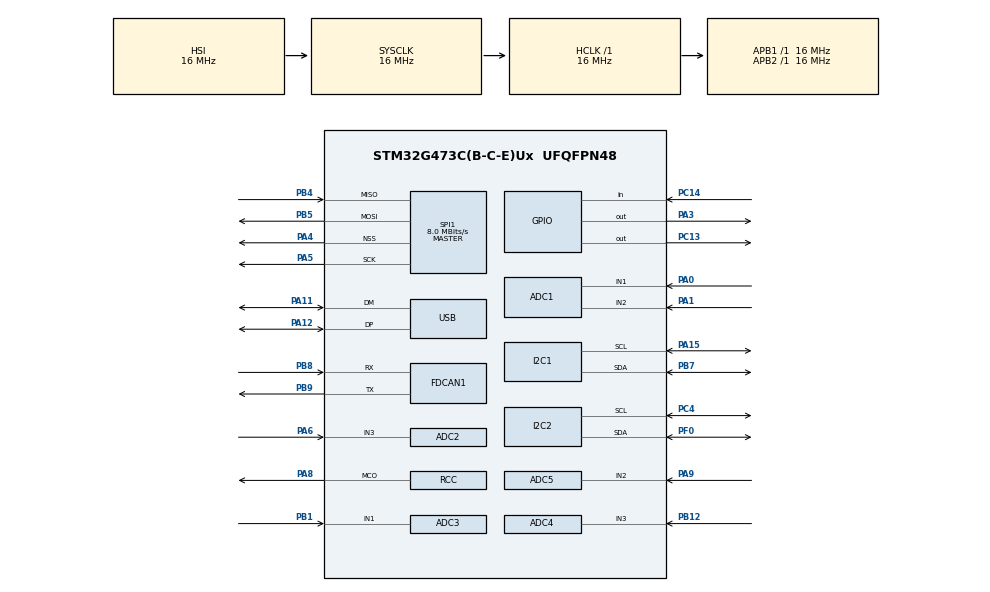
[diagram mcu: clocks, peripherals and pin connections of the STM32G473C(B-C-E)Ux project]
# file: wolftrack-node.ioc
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ADC1.Channel-0\#ChannelRegularConversion=ADC_CHANNEL_1
ADC1.NbrOfConversionFlag=1
ADC1.OffsetNumber-0\#ChannelRegularConversion=ADC_OFFSET_NONE
ADC1.Rank-0\#ChannelRegularConversion=1
ADC1.SamplingTime-0\#ChannelRegularConversion=ADC_SAMPLETIME_2CYCLES_5
ADC1.master=1
ADC2.Channel-3\#ChannelRegularConversion=ADC_CHANNEL_3
ADC2.NbrOfConversionFlag=1
ADC2.OffsetNumber-3\#ChannelRegularConversion=ADC_OFFSET_NONE
ADC2.Rank-3\#ChannelRegularConversion=1
ADC2.SamplingTime-3\#ChannelRegularConversion=ADC_SAMPLETIME_2CYCLES_5
ADC3.Channel-2\#ChannelRegularConversion=ADC_CHANNEL_1
ADC3.NbrOfConversionFlag=1
ADC3.OffsetNumber-2\#ChannelRegularConversion=ADC_OFFSET_NONE
ADC3.Rank-2\#ChannelRegularConversion=1
ADC3.SamplingTime-2\#ChannelRegularConversion=ADC_SAMPLETIME_2CYCLES_5
ADC3.master=1
ADC4.Channel-1\#ChannelRegularConversion=ADC_CHANNEL_3
ADC4.NbrOfConversionFlag=1
ADC4.OffsetNumber-1\#ChannelRegularConversion=ADC_OFFSET_NONE
ADC4.Rank-1\#ChannelRegularConversion=1
ADC4.SamplingTime-1\#ChannelRegularConversion=ADC_SAMPLETIME_2CYCLES_5
ADC5.Channel-3\#ChannelRegularConversion=ADC_CHANNEL_2
ADC5.NbrOfConversionFlag=1
ADC5.OffsetNumber-3\#ChannelRegularConversion=ADC_OFFSET_NONE
ADC5.Rank-3\#ChannelRegularConversion=1
ADC5.SamplingTime-3\#ChannelRegularConversion=ADC_SAMPLETIME_2CYCLES_5
FDCAN1.CalculateBaudRateNominal=333333
FDCAN1.CalculateTimeBitNominal=3000
FDCAN1.CalculateTimeQuantumNominal=1000.0
FREERTOS.Tasks01=defaultTask,24,128,StartDefaultTask,Default,NULL,Dynamic,NULL,NULL
I2C1.Timing=0x00503D58
I2C2.Timing=0x00503D58
Mcu.Family=STM32G4
Mcu.Name=STM32G473C(B-C-E)Ux
Mcu.Package=UFQFPN48
NVIC.PriorityGroup=NVIC_PRIORITYGROUP_4
NVIC.TIM1_UP_TIM16_IRQn=true\:15\:0\:false\:false\:true\:false\:false\:true\:true
NVIC.TimeBase=TIM1_UP_TIM16_IRQn
NVIC.TimeBaseIP=TIM1
NVIC.USB_LP_IRQn=true\:5\:0\:false\:false\:true\:true\:false\:true\:true
PA0.Mode=IN1-Single-Ended
PA0.Signal=ADC1_IN1
PA1.Mode=IN2-Single-Ended
PA1.Signal=ADC1_IN2
PA11.Mode=Device
PA11.Signal=USB_DM
PA12.Mode=Device
PA12.Signal=USB_DP
PA13.Mode=Trace_Asynchronous_SW
PA13.Signal=SYS_JTMS-SWDIO
PA14.Mode=Trace_Asynchronous_SW
PA14.Signal=SYS_JTCK-SWCLK
PA15.Mode=I2C
PA15.Signal=I2C1_SCL
PA3.Signal=GPIO_Output
PA4.Mode=NSS_Signal_Hard_Output
PA4.Signal=SPI1_NSS
PA5.Mode=Full_Duplex_Master
PA5.Signal=SPI1_SCK
PA6.Mode=IN3-Single-Ended
PA6.Signal=ADC2_IN3
PA8.GPIO_Speed=GPIO_SPEED_FREQ_VERY_HIGH
PA8.Mode=Clock-out
PA8.Signal=RCC_MCO
PA9.Mode=IN2-Single-Ended
PA9.Signal=ADC5_IN2
PB1.Mode=IN1-Single-Ended
PB1.Signal=ADC3_IN1
PB12.Mode=IN3-Single-Ended
PB12.Signal=ADC4_IN3
PB3.Mode=Trace_Asynchronous_SW
PB3.Signal=SYS_JTDO-SWO
PB4.Mode=Full_Duplex_Master
PB4.Signal=SPI1_MISO
PB5.Mode=Full_Duplex_Master
PB5.Signal=SPI1_MOSI
PB7.Mode=I2C
PB7.Signal=I2C1_SDA
PB8-BOOT0.Mode=FDCAN_Activate
PB8-BOOT0.Signal=FDCAN1_RX
PB9.Mode=FDCAN_Activate
PB9.Signal=FDCAN1_TX
PC13.Signal=GPIO_Output
PC14-OSC32_IN.GPIO_PuPd=GPIO_PULLUP
PC14-OSC32_IN.Signal=GPIO_Input
PC4.Mode=I2C
PC4.Signal=I2C2_SCL
PF0-OSC_IN.Mode=I2C
PF0-OSC_IN.Signal=I2C2_SDA
ProjectManager.HeapSize=0x200
ProjectManager.StackSize=0x400
ProjectManager.TargetToolchain=CMake
RCC.ADC12Freq_Value=16000000
RCC.ADC345Freq_Value=16000000
RCC.AHBFreq_Value=16000000
RCC.APB1Freq_Value=16000000
RCC.APB1TimFreq_Value=16000000
RCC.APB2Freq_Value=16000000
RCC.APB2TimFreq_Value=16000000
RCC.CortexFreq_Value=16000000
RCC.EXTERNAL_CLOCK_VALUE=12288000
RCC.HCLKFreq_Value=16000000
RCC.HSE_VALUE=8000000
RCC.HSI48_VALUE=48000000
RCC.HSI_VALUE=16000000
RCC.LSE_VALUE=32768
RCC.PLLN=12
RCC.PLLQ=RCC_PLLQ_DIV4
RCC.RCC_MCODiv=RCC_MCODIV_4
RCC.SYSCLKFreq_VALUE=16000000
RCC.USBFreq_Value=48000000
RCC.VCOOutputFreq_Value=192000000
SPI1.CalculateBaudRate=8.0 MBits/s
SPI1.Direction=SPI_DIRECTION_2LINES
SPI1.Mode=SPI_MODE_MASTER
SPI1.VirtualNSS=VM_NSSHARD
SPI1.VirtualType=VM_MASTER
USB_DEVICE.CLASS_NAME_FS=CDC
USB_DEVICE.VirtualMode=Cdc
USB_DEVICE.VirtualModeFS=Cdc_FS
VP_FREERTOS_VS_CMSIS_V2.Mode=CMSIS_V2
VP_SYS_VS_DBSignals.Mode=DisableDeadBatterySignals
VP_SYS_VS_tim1.Mode=TIM1
VP_USB_DEVICE_VS_USB_DEVICE_CDC_FS.Mode=CDC_FS
board=custom

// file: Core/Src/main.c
/* USER CODE BEGIN Header */
/**
  ******************************************************************************
  * @file           : main.c
  * @brief          : Main program body
  ******************************************************************************
  * @attention
  *
  * Copyright (c) 2026 STMicroelectronics.
  * All rights reserved.
  *
  * This software is licensed under terms that can be found in the LICENSE file
  * in the root directory of this software component.
  * If no LICENSE file comes with this software, it is provided AS-IS.
  *
  ******************************************************************************
  */
/* USER CODE END Header */
#include "main.h"
#include "cmsis_os.h"
#include "usb_device.h"

/* USER CODE BEGIN Includes */

#include "dfu_trigger.h"
#include "usb_identity.h"

/* USER CODE END Includes */

ADC_HandleTypeDef hadc1;
ADC_HandleTypeDef hadc2;
ADC_HandleTypeDef hadc3;
ADC_HandleTypeDef hadc4;
ADC_HandleTypeDef hadc5;

FDCAN_HandleTypeDef hfdcan1;

I2C_HandleTypeDef hi2c1;
I2C_HandleTypeDef hi2c2;

SPI_HandleTypeDef hspi1;

/* Definitions for defaultTask */
osThreadId_t defaultTaskHandle;
const osThreadAttr_t defaultTask_attributes = {
  .name = "defaultTask",
  .priority = (osPriority_t) osPriorityNormal,
  .stack_size = 128 * 4
};

void SystemClock_Config(void);
static void MX_GPIO_Init(void);
static void MX_ADC1_Init(void);
static void MX_ADC2_Init(void);
static void MX_ADC3_Init(void);
static void MX_ADC4_Init(void);
static void MX_ADC5_Init(void);
static void MX_FDCAN1_Init(void);
static void MX_I2C1_Init(void);
static void MX_I2C2_Init(void);
static void MX_SPI1_Init(void);
void StartDefaultTask(void *argument);

int main(void)
{

  /* USER CODE BEGIN 1 */

  app_early_boot_dfu_check();

  /* USER CODE END 1 */

  /* MCU Configuration--------------------------------------------------------*/

  /* Reset of all peripherals, Initializes the Flash interface and the Systick. */
  HAL_Init();

  /* Configure the system clock */
  SystemClock_Config();

  /* Initialize all configured peripherals */
  MX_GPIO_Init();
  MX_ADC1_Init();
  MX_ADC2_Init();
  MX_ADC3_Init();
  MX_ADC4_Init();
  MX_ADC5_Init();
  MX_FDCAN1_Init();
  MX_I2C1_Init();
  MX_I2C2_Init();
  MX_SPI1_Init();

  /* Init scheduler */
  osKernelInitialize();

  /* Create the thread(s) */
  /* creation of defaultTask */
  defaultTaskHandle = osThreadNew(StartDefaultTask, NULL, &defaultTask_attributes);

  /* Start scheduler */
  osKernelStart();

  /* We should never get here as control is now taken by the scheduler */

  /* Infinite loop */
  while (1)
  {

  }
}

void SystemClock_Config(void)
{
  RCC_OscInitTypeDef RCC_OscInitStruct = {0};
  RCC_ClkInitTypeDef RCC_ClkInitStruct = {0};

  /** Configure the main internal regulator output voltage
  */
  HAL_PWREx_ControlVoltageScaling(PWR_REGULATOR_VOLTAGE_SCALE1);

  /** Initializes the RCC Oscillators according to the specified parameters
  * in the RCC_OscInitTypeDef structure.
  */
  RCC_OscInitStruct.OscillatorType = RCC_OSCILLATORTYPE_HSI;
  RCC_OscInitStruct.HSIState = RCC_HSI_ON;
  RCC_OscInitStruct.HSICalibrationValue = RCC_HSICALIBRATION_DEFAULT;
  RCC_OscInitStruct.PLL.PLLState = RCC_PLL_ON;
  RCC_OscInitStruct.PLL.PLLSource = RCC_PLLSOURCE_HSI;
  RCC_OscInitStruct.PLL.PLLM = RCC_PLLM_DIV1;
  RCC_OscInitStruct.PLL.PLLN = 12;
  RCC_OscInitStruct.PLL.PLLP = RCC_PLLP_DIV2;
  RCC_OscInitStruct.PLL.PLLQ = RCC_PLLQ_DIV4;
  RCC_OscInitStruct.PLL.PLLR = RCC_PLLR_DIV2;
  if (HAL_RCC_OscConfig(&RCC_OscInitStruct) != HAL_OK)
  {
    Error_Handler();
  }

  /** Initializes the CPU, AHB and APB buses clocks
  */
  RCC_ClkInitStruct.ClockType = RCC_CLOCKTYPE_HCLK|RCC_CLOCKTYPE_SYSCLK
                              |RCC_CLOCKTYPE_PCLK1|RCC_CLOCKTYPE_PCLK2;
  RCC_ClkInitStruct.SYSCLKSource = RCC_SYSCLKSOURCE_HSI;
  RCC_ClkInitStruct.AHBCLKDivider = RCC_SYSCLK_DIV1;
  RCC_ClkInitStruct.APB1CLKDivider = RCC_HCLK_DIV1;
  RCC_ClkInitStruct.APB2CLKDivider = RCC_HCLK_DIV1;

  if (HAL_RCC_ClockConfig(&RCC_ClkInitStruct, FLASH_LATENCY_0) != HAL_OK)
  {
    Error_Handler();
  }
  HAL_RCC_MCOConfig(RCC_MCO1, RCC_MCO1SOURCE_HSI, RCC_MCODIV_4);
}

static void MX_ADC1_Init(void)
{

  ADC_MultiModeTypeDef multimode = {0};
  ADC_ChannelConfTypeDef sConfig = {0};

  /** Common config
  */
  hadc1.Instance = ADC1;
  hadc1.Init.ClockPrescaler = ADC_CLOCK_SYNC_PCLK_DIV2;
  hadc1.Init.Resolution = ADC_RESOLUTION_12B;
  hadc1.Init.DataAlign = ADC_DATAALIGN_RIGHT;
  hadc1.Init.GainCompensation = 0;
  hadc1.Init.ScanConvMode = ADC_SCAN_DISABLE;
  hadc1.Init.EOCSelection = ADC_EOC_SINGLE_CONV;
  hadc1.Init.LowPowerAutoWait = DISABLE;
  hadc1.Init.ContinuousConvMode = DISABLE;
  hadc1.Init.NbrOfConversion = 1;
  hadc1.Init.DiscontinuousConvMode = DISABLE;
  hadc1.Init.ExternalTrigConv = ADC_SOFTWARE_START;
  hadc1.Init.ExternalTrigConvEdge = ADC_EXTERNALTRIGCONVEDGE_NONE;
  hadc1.Init.DMAContinuousRequests = DISABLE;
  hadc1.Init.Overrun = ADC_OVR_DATA_PRESERVED;
  hadc1.Init.OversamplingMode = DISABLE;
  if (HAL_ADC_Init(&hadc1) != HAL_OK)
  {
    Error_Handler();
  }

  /** Configure the ADC multi-mode
  */
  multimode.Mode = ADC_MODE_INDEPENDENT;
  if (HAL_ADCEx_MultiModeConfigChannel(&hadc1, &multimode) != HAL_OK)
  {
    Error_Handler();
  }

  /** Configure Regular Channel
  */
  sConfig.Channel = ADC_CHANNEL_1;
  sConfig.Rank = ADC_REGULAR_RANK_1;
  sConfig.SamplingTime = ADC_SAMPLETIME_2CYCLES_5;
  sConfig.SingleDiff = ADC_SINGLE_ENDED;
  sConfig.OffsetNumber = ADC_OFFSET_NONE;
  sConfig.Offset = 0;
  if (HAL_ADC_ConfigChannel(&hadc1, &sConfig) != HAL_OK)
  {
    Error_Handler();
  }

}

static void MX_ADC2_Init(void)
{

  ADC_ChannelConfTypeDef sConfig = {0};

  /** Common config
  */
  hadc2.Instance = ADC2;
  hadc2.Init.ClockPrescaler = ADC_CLOCK_SYNC_PCLK_DIV2;
  hadc2.Init.Resolution = ADC_RESOLUTION_12B;
  hadc2.Init.DataAlign = ADC_DATAALIGN_RIGHT;
  hadc2.Init.GainCompensation = 0;
  hadc2.Init.ScanConvMode = ADC_SCAN_DISABLE;
  hadc2.Init.EOCSelection = ADC_EOC_SINGLE_CONV;
  hadc2.Init.LowPowerAutoWait = DISABLE;
  hadc2.Init.ContinuousConvMode = DISABLE;
  hadc2.Init.NbrOfConversion = 1;
  hadc2.Init.DiscontinuousConvMode = DISABLE;
  hadc2.Init.ExternalTrigConv = ADC_SOFTWARE_START;
  hadc2.Init.ExternalTrigConvEdge = ADC_EXTERNALTRIGCONVEDGE_NONE;
  hadc2.Init.DMAContinuousRequests = DISABLE;
  hadc2.Init.Overrun = ADC_OVR_DATA_PRESERVED;
  hadc2.Init.OversamplingMode = DISABLE;
  if (HAL_ADC_Init(&hadc2) != HAL_OK)
  {
    Error_Handler();
  }

  /** Configure Regular Channel
  */
  sConfig.Channel = ADC_CHANNEL_3;
  sConfig.Rank = ADC_REGULAR_RANK_1;
  sConfig.SamplingTime = ADC_SAMPLETIME_2CYCLES_5;
  sConfig.SingleDiff = ADC_SINGLE_ENDED;
  sConfig.OffsetNumber = ADC_OFFSET_NONE;
  sConfig.Offset = 0;
  if (HAL_ADC_ConfigChannel(&hadc2, &sConfig) != HAL_OK)
  {
    Error_Handler();
  }

}

static void MX_ADC3_Init(void)
{

  ADC_MultiModeTypeDef multimode = {0};
  ADC_ChannelConfTypeDef sConfig = {0};

  /** Common config
  */
  hadc3.Instance = ADC3;
  hadc3.Init.ClockPrescaler = ADC_CLOCK_SYNC_PCLK_DIV2;
  hadc3.Init.Resolution = ADC_RESOLUTION_12B;
  hadc3.Init.DataAlign = ADC_DATAALIGN_RIGHT;
  hadc3.Init.GainCompensation = 0;
  hadc3.Init.ScanConvMode = ADC_SCAN_DISABLE;
  hadc3.Init.EOCSelection = ADC_EOC_SINGLE_CONV;
  hadc3.Init.LowPowerAutoWait = DISABLE;
  hadc3.Init.ContinuousConvMode = DISABLE;
  hadc3.Init.NbrOfConversion = 1;
  hadc3.Init.DiscontinuousConvMode = DISABLE;
  hadc3.Init.ExternalTrigConv = ADC_SOFTWARE_START;
  hadc3.Init.ExternalTrigConvEdge = ADC_EXTERNALTRIGCONVEDGE_NONE;
  hadc3.Init.DMAContinuousRequests = DISABLE;
  hadc3.Init.Overrun = ADC_OVR_DATA_PRESERVED;
  hadc3.Init.OversamplingMode = DISABLE;
  if (HAL_ADC_Init(&hadc3) != HAL_OK)
  {
    Error_Handler();
  }

  /** Configure the ADC multi-mode
  */
  multimode.Mode = ADC_MODE_INDEPENDENT;
  if (HAL_ADCEx_MultiModeConfigChannel(&hadc3, &multimode) != HAL_OK)
  {
    Error_Handler();
  }

  /** Configure Regular Channel
  */
  sConfig.Channel = ADC_CHANNEL_1;
  sConfig.Rank = ADC_REGULAR_RANK_1;
  sConfig.SamplingTime = ADC_SAMPLETIME_2CYCLES_5;
  sConfig.SingleDiff = ADC_SINGLE_ENDED;
  sConfig.OffsetNumber = ADC_OFFSET_NONE;
  sConfig.Offset = 0;
  if (HAL_ADC_ConfigChannel(&hadc3, &sConfig) != HAL_OK)
  {
    Error_Handler();
  }

}

static void MX_ADC4_Init(void)
{

  ADC_ChannelConfTypeDef sConfig = {0};

  /** Common config
  */
  hadc4.Instance = ADC4;
  hadc4.Init.ClockPrescaler = ADC_CLOCK_SYNC_PCLK_DIV2;
  hadc4.Init.Resolution = ADC_RESOLUTION_12B;
  hadc4.Init.DataAlign = ADC_DATAALIGN_RIGHT;
  hadc4.Init.GainCompensation = 0;
  hadc4.Init.ScanConvMode = ADC_SCAN_DISABLE;
  hadc4.Init.EOCSelection = ADC_EOC_SINGLE_CONV;
  hadc4.Init.LowPowerAutoWait = DISABLE;
  hadc4.Init.ContinuousConvMode = DISABLE;
  hadc4.Init.NbrOfConversion = 1;
  hadc4.Init.DiscontinuousConvMode = DISABLE;
  hadc4.Init.ExternalTrigConv = ADC_SOFTWARE_START;
  hadc4.Init.ExternalTrigConvEdge = ADC_EXTERNALTRIGCONVEDGE_NONE;
  hadc4.Init.DMAContinuousRequests = DISABLE;
  hadc4.Init.Overrun = ADC_OVR_DATA_PRESERVED;
  hadc4.Init.OversamplingMode = DISABLE;
  if (HAL_ADC_Init(&hadc4) != HAL_OK)
  {
    Error_Handler();
  }

  /** Configure Regular Channel
  */
  sConfig.Channel = ADC_CHANNEL_3;
  sConfig.Rank = ADC_REGULAR_RANK_1;
  sConfig.SamplingTime = ADC_SAMPLETIME_2CYCLES_5;
  sConfig.SingleDiff = ADC_SINGLE_ENDED;
  sConfig.OffsetNumber = ADC_OFFSET_NONE;
  sConfig.Offset = 0;
  if (HAL_ADC_ConfigChannel(&hadc4, &sConfig) != HAL_OK)
  {
    Error_Handler();
  }

}

static void MX_ADC5_Init(void)
{

  ADC_ChannelConfTypeDef sConfig = {0};

  /** Common config
  */
  hadc5.Instance = ADC5;
  hadc5.Init.ClockPrescaler = ADC_CLOCK_SYNC_PCLK_DIV2;
  hadc5.Init.Resolution = ADC_RESOLUTION_12B;
  hadc5.Init.DataAlign = ADC_DATAALIGN_RIGHT;
  hadc5.Init.GainCompensation = 0;
  hadc5.Init.ScanConvMode = ADC_SCAN_DISABLE;
  hadc5.Init.EOCSelection = ADC_EOC_SINGLE_CONV;
  hadc5.Init.LowPowerAutoWait = DISABLE;
  hadc5.Init.ContinuousConvMode = DISABLE;
  hadc5.Init.NbrOfConversion = 1;
  hadc5.Init.DiscontinuousConvMode = DISABLE;
  hadc5.Init.ExternalTrigConv = ADC_SOFTWARE_START;
  hadc5.Init.ExternalTrigConvEdge = ADC_EXTERNALTRIGCONVEDGE_NONE;
  hadc5.Init.DMAContinuousRequests = DISABLE;
  hadc5.Init.Overrun = ADC_OVR_DATA_PRESERVED;
  hadc5.Init.OversamplingMode = DISABLE;
  if (HAL_ADC_Init(&hadc5) != HAL_OK)
  {
    Error_Handler();
  }

  /** Configure Regular Channel
  */
  sConfig.Channel = ADC_CHANNEL_2;
  sConfig.Rank = ADC_REGULAR_RANK_1;
  sConfig.SamplingTime = ADC_SAMPLETIME_2CYCLES_5;
  sConfig.SingleDiff = ADC_SINGLE_ENDED;
  sConfig.OffsetNumber = ADC_OFFSET_NONE;
  sConfig.Offset = 0;
  if (HAL_ADC_ConfigChannel(&hadc5, &sConfig) != HAL_OK)
  {
    Error_Handler();
  }

}

static void MX_FDCAN1_Init(void)
{

  hfdcan1.Instance = FDCAN1;
  hfdcan1.Init.ClockDivider = FDCAN_CLOCK_DIV1;
  hfdcan1.Init.FrameFormat = FDCAN_FRAME_CLASSIC;
  hfdcan1.Init.Mode = FDCAN_MODE_NORMAL;
  hfdcan1.Init.AutoRetransmission = DISABLE;
  hfdcan1.Init.TransmitPause = DISABLE;
  hfdcan1.Init.ProtocolException = DISABLE;
  hfdcan1.Init.NominalPrescaler = 16;
  hfdcan1.Init.NominalSyncJumpWidth = 1;
  hfdcan1.Init.NominalTimeSeg1 = 1;
  hfdcan1.Init.NominalTimeSeg2 = 1;
  hfdcan1.Init.DataPrescaler = 1;
  hfdcan1.Init.DataSyncJumpWidth = 1;
  hfdcan1.Init.DataTimeSeg1 = 1;
  hfdcan1.Init.DataTimeSeg2 = 1;
  hfdcan1.Init.StdFiltersNbr = 0;
  hfdcan1.Init.ExtFiltersNbr = 0;
  hfdcan1.Init.TxFifoQueueMode = FDCAN_TX_FIFO_OPERATION;
  if (HAL_FDCAN_Init(&hfdcan1) != HAL_OK)
  {
    Error_Handler();
  }

}

static void MX_I2C1_Init(void)
{

  hi2c1.Instance = I2C1;
  hi2c1.Init.Timing = 0x00503D58;
  hi2c1.Init.OwnAddress1 = 0;
  hi2c1.Init.AddressingMode = I2C_ADDRESSINGMODE_7BIT;
  hi2c1.Init.DualAddressMode = I2C_DUALADDRESS_DISABLE;
  hi2c1.Init.OwnAddress2 = 0;
  hi2c1.Init.OwnAddress2Masks = I2C_OA2_NOMASK;
  hi2c1.Init.GeneralCallMode = I2C_GENERALCALL_DISABLE;
  hi2c1.Init.NoStretchMode = I2C_NOSTRETCH_DISABLE;
  if (HAL_I2C_Init(&hi2c1) != HAL_OK)
  {
    Error_Handler();
  }

  /** Configure Analogue filter
  */
  if (HAL_I2CEx_ConfigAnalogFilter(&hi2c1, I2C_ANALOGFILTER_ENABLE) != HAL_OK)
  {
    Error_Handler();
  }

  /** Configure Digital filter
  */
  if (HAL_I2CEx_ConfigDigitalFilter(&hi2c1, 0) != HAL_OK)
  {
    Error_Handler();
  }

}

static void MX_I2C2_Init(void)
{

  hi2c2.Instance = I2C2;
  hi2c2.Init.Timing = 0x00503D58;
  hi2c2.Init.OwnAddress1 = 0;
  hi2c2.Init.AddressingMode = I2C_ADDRESSINGMODE_7BIT;
  hi2c2.Init.DualAddressMode = I2C_DUALADDRESS_DISABLE;
  hi2c2.Init.OwnAddress2 = 0;
  hi2c2.Init.OwnAddress2Masks = I2C_OA2_NOMASK;
  hi2c2.Init.GeneralCallMode = I2C_GENERALCALL_DISABLE;
  hi2c2.Init.NoStretchMode = I2C_NOSTRETCH_DISABLE;
  if (HAL_I2C_Init(&hi2c2) != HAL_OK)
  {
    Error_Handler();
  }

  /** Configure Analogue filter
  */
  if (HAL_I2CEx_ConfigAnalogFilter(&hi2c2, I2C_ANALOGFILTER_ENABLE) != HAL_OK)
  {
    Error_Handler();
  }

  /** Configure Digital filter
  */
  if (HAL_I2CEx_ConfigDigitalFilter(&hi2c2, 0) != HAL_OK)
  {
    Error_Handler();
  }

}

static void MX_SPI1_Init(void)
{

  /* SPI1 parameter configuration*/
  hspi1.Instance = SPI1;
  hspi1.Init.Mode = SPI_MODE_MASTER;
  hspi1.Init.Direction = SPI_DIRECTION_2LINES;
  hspi1.Init.DataSize = SPI_DATASIZE_4BIT;
  hspi1.Init.CLKPolarity = SPI_POLARITY_LOW;
  hspi1.Init.CLKPhase = SPI_PHASE_1EDGE;
  hspi1.Init.NSS = SPI_NSS_HARD_OUTPUT;
  hspi1.Init.BaudRatePrescaler = SPI_BAUDRATEPRESCALER_2;
  hspi1.Init.FirstBit = SPI_FIRSTBIT_MSB;
  hspi1.Init.TIMode = SPI_TIMODE_DISABLE;
  hspi1.Init.CRCCalculation = SPI_CRCCALCULATION_DISABLE;
  hspi1.Init.CRCPolynomial = 7;
  hspi1.Init.CRCLength = SPI_CRC_LENGTH_DATASIZE;
  hspi1.Init.NSSPMode = SPI_NSS_PULSE_ENABLE;
  if (HAL_SPI_Init(&hspi1) != HAL_OK)
  {
    Error_Handler();
  }

}

static void MX_GPIO_Init(void)
{
  GPIO_InitTypeDef GPIO_InitStruct = {0};

  /* GPIO Ports Clock Enable */
  __HAL_RCC_GPIOC_CLK_ENABLE();
  __HAL_RCC_GPIOF_CLK_ENABLE();
  __HAL_RCC_GPIOA_CLK_ENABLE();
  __HAL_RCC_GPIOB_CLK_ENABLE();

  /*Configure GPIO pin Output Level */
  HAL_GPIO_WritePin(GPIOC, GPIO_PIN_13, GPIO_PIN_RESET);

  /*Configure GPIO pin Output Level */
  HAL_GPIO_WritePin(GPIOA, GPIO_PIN_3, GPIO_PIN_RESET);

  /*Configure GPIO pin : PC13 */
  GPIO_InitStruct.Pin = GPIO_PIN_13;
  GPIO_InitStruct.Mode = GPIO_MODE_OUTPUT_PP;
  GPIO_InitStruct.Pull = GPIO_NOPULL;
  GPIO_InitStruct.Speed = GPIO_SPEED_FREQ_LOW;
  HAL_GPIO_Init(GPIOC, &GPIO_InitStruct);

  /*Configure GPIO pin : PC14 */
  GPIO_InitStruct.Pin = GPIO_PIN_14;
  GPIO_InitStruct.Mode = GPIO_MODE_INPUT;
  GPIO_InitStruct.Pull = GPIO_PULLUP;
  HAL_GPIO_Init(GPIOC, &GPIO_InitStruct);

  /*Configure GPIO pin : PA3 */
  GPIO_InitStruct.Pin = GPIO_PIN_3;
  GPIO_InitStruct.Mode = GPIO_MODE_OUTPUT_PP;
  GPIO_InitStruct.Pull = GPIO_NOPULL;
  GPIO_InitStruct.Speed = GPIO_SPEED_FREQ_LOW;
  HAL_GPIO_Init(GPIOA, &GPIO_InitStruct);

  /*Configure GPIO pin : PA8 */
  GPIO_InitStruct.Pin = GPIO_PIN_8;
  GPIO_InitStruct.Mode = GPIO_MODE_AF_PP;
  GPIO_InitStruct.Pull = GPIO_NOPULL;
  GPIO_InitStruct.Speed = GPIO_SPEED_FREQ_VERY_HIGH;
  GPIO_InitStruct.Alternate = GPIO_AF0_MCO;
  HAL_GPIO_Init(GPIOA, &GPIO_InitStruct);

}

void StartDefaultTask(void *argument)
{
  /* init code for USB_Device */
  MX_USB_Device_Init();
  /* USER CODE BEGIN 5 */
  /* Infinite loop */
  for(;;)
  {
    app_poll_dfu_trigger();
    app_poll_usb_identity();
    osDelay(1);
  }
  /* USER CODE END 5 */
}

void HAL_TIM_PeriodElapsedCallback(TIM_HandleTypeDef *htim)
{
  if (htim->Instance == TIM1)
  {
    HAL_IncTick();
  }
}

void Error_Handler(void)
{
  __disable_irq();
  while (1)
  {
  }
}
